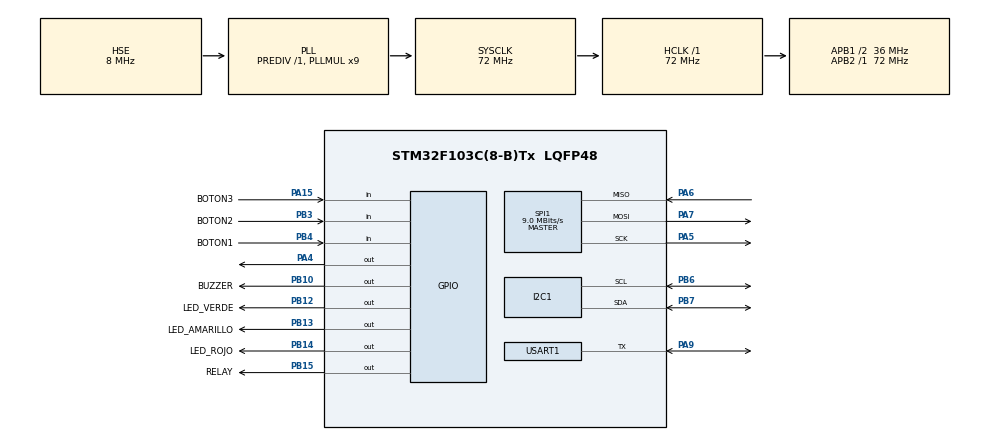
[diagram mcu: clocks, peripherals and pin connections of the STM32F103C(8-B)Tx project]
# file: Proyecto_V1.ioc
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FATFS._MAX_SS=4096
FATFS._USE_LFN=2
FREERTOS.Tasks01=defaultTask,24,128,StartDefaultTask,Default,NULL,Dynamic,NULL,NULL
FREERTOS.configUSE_NEWLIB_REENTRANT=1
Mcu.Family=STM32F1
Mcu.Name=STM32F103C(8-B)Tx
Mcu.Package=LQFP48
NVIC.PriorityGroup=NVIC_PRIORITYGROUP_4
NVIC.TIM4_IRQn=true\:15\:0\:false\:false\:true\:false\:false\:true\:true
NVIC.TimeBase=TIM4_IRQn
NVIC.TimeBaseIP=TIM4
NVIC.USART1_IRQn=true\:5\:0\:false\:false\:true\:true\:true\:true\:true
PA13.Mode=Serial_Wire
PA13.Signal=SYS_JTMS-SWDIO
PA14.Mode=Serial_Wire
PA14.Signal=SYS_JTCK-SWCLK
PA15.GPIO_Label=BOTON3
PA15.GPIO_PuPd=GPIO_PULLUP
PA15.Signal=GPIO_Input
PA4.Signal=GPIO_Output
PA5.Mode=Full_Duplex_Master
PA5.Signal=SPI1_SCK
PA6.Mode=Full_Duplex_Master
PA6.Signal=SPI1_MISO
PA7.Mode=Full_Duplex_Master
PA7.Signal=SPI1_MOSI
PA9.Mode=Half_duplex(single_wire_mode)
PA9.Signal=USART1_TX
PB10.GPIO_Label=BUZZER
PB10.Signal=GPIO_Output
PB12.GPIO_Label=LED_VERDE
PB12.Signal=GPIO_Output
PB13.GPIO_Label=LED_AMARILLO
PB13.Signal=GPIO_Output
PB14.GPIO_Label=LED_ROJO
PB14.Signal=GPIO_Output
PB15.GPIO_Label=RELAY
PB15.Signal=GPIO_Output
PB3.GPIO_Label=BOTON2
PB3.GPIO_PuPd=GPIO_PULLUP
PB3.Signal=GPIO_Input
PB4.GPIO_Label=BOTON1
PB4.GPIO_PuPd=GPIO_PULLUP
PB4.Signal=GPIO_Input
PB6.Mode=I2C
PB6.Signal=I2C1_SCL
PB7.Mode=I2C
PB7.Signal=I2C1_SDA
PD0-OSC_IN.Mode=HSE-External-Oscillator
PD0-OSC_IN.Signal=RCC_OSC_IN
PD1-OSC_OUT.Mode=HSE-External-Oscillator
PD1-OSC_OUT.Signal=RCC_OSC_OUT
ProjectManager.HeapSize=0x200
ProjectManager.StackSize=0x400
ProjectManager.TargetToolchain=STM32CubeIDE
RCC.AHBFreq_Value=72000000
RCC.APB1CLKDivider=RCC_HCLK_DIV2
RCC.APB1Freq_Value=36000000
RCC.APB1TimFreq_Value=72000000
RCC.APB2Freq_Value=72000000
RCC.APB2TimFreq_Value=72000000
RCC.HCLKFreq_Value=72000000
RCC.PLLMUL=RCC_PLL_MUL9
RCC.PLLSourceVirtual=RCC_PLLSOURCE_HSE
RCC.SYSCLKFreq_VALUE=72000000
RCC.SYSCLKSource=RCC_SYSCLKSOURCE_PLLCLK
RCC.USBFreq_Value=72000000
SPI1.BaudRatePrescaler=SPI_BAUDRATEPRESCALER_8
SPI1.CalculateBaudRate=9.0 MBits/s
SPI1.Direction=SPI_DIRECTION_2LINES
SPI1.Mode=SPI_MODE_MASTER
SPI1.VirtualType=VM_MASTER
USART1.VirtualMode=VM_ASYNC
VP_FATFS_VS_Generic.Mode=User_defined
VP_FREERTOS_VS_CMSIS_V2.Mode=CMSIS_V2
VP_SYS_VS_tim4.Mode=TIM4
board=custom

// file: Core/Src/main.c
/* USER CODE BEGIN Header */
/**
  ******************************************************************************
  * @file           : main.c
  * @brief          : Main program body
  ******************************************************************************
  * @attention
  *
  * Copyright (c) 2022 STMicroelectronics.
  * All rights reserved.
  *
  * This software is licensed under terms that can be found in the LICENSE file
  * in the root directory of this software component.
  * If no LICENSE file comes with this software, it is provided AS-IS.
  *
  ******************************************************************************
  */
/* USER CODE END Header */
#include "main.h"
#include "cmsis_os.h"
#include "fatfs.h"

/* USER CODE BEGIN Includes */
#include "liquidcrystal_i2c.h"
#include "OneWire.h"
#include "my_ftoa.h"
#include "funciones.h"
#include "stdio.h"
/* USER CODE END Includes */

 I2C_HandleTypeDef hi2c1;

SPI_HandleTypeDef hspi1;

UART_HandleTypeDef huart1;

/* Definitions for defaultTask */
osThreadId_t defaultTaskHandle;
const osThreadAttr_t defaultTask_attributes = {
  .name = "defaultTask",
  .stack_size = 128 * 4,
  .priority = (osPriority_t) osPriorityNormal,
};

void SystemClock_Config(void);
static void MX_GPIO_Init(void);
static void MX_I2C1_Init(void);
static void MX_USART1_UART_Init(void);
static void MX_SPI1_Init(void);
void StartDefaultTask(void *argument);

/* USER CODE BEGIN 0 */
extern float Temp[MAXDEVICES_ON_THE_BUS];
/* USER CODE END 0 */

int main(void)
{

  /* MCU Configuration--------------------------------------------------------*/

  /* Reset of all peripherals, Initializes the Flash interface and the Systick. */
  HAL_Init();

  /* Configure the system clock */
  SystemClock_Config();

  /* Initialize all configured peripherals */
  MX_GPIO_Init();
  MX_I2C1_Init();
  MX_USART1_UART_Init();
  MX_SPI1_Init();
  MX_FATFS_Init();
  /* USER CODE BEGIN 2 */

  InitAll(); // Inicializa todo

  /* USER CODE END 2 */

  /* Init scheduler */
  osKernelInitialize();

  /* Create the thread(s) */
  /* creation of defaultTask */
  defaultTaskHandle = osThreadNew(StartDefaultTask, NULL, &defaultTask_attributes);

  /* USER CODE BEGIN RTOS_THREADS */
  /* add threads, ... */
  xTaskCreate(MdE_Principal, "MdE Principal", configMINIMAL_STACK_SIZE, NULL, 1, NULL);
  xTaskCreate(MdE_Preparar, "MdE Preparando", configMINIMAL_STACK_SIZE, NULL, 2, NULL);
  xTaskCreate(Tarea_Errores, "Chequeo Errores", configMINIMAL_STACK_SIZE, NULL, 1, NULL);
  xTaskCreate(Tarea_Botones, "Tarea Botones", configMINIMAL_STACK_SIZE, NULL, 1, NULL);
  /* USER CODE END RTOS_THREADS */

  /* Start scheduler */
  osKernelStart();

  /* We should never get here as control is now taken by the scheduler */
  /* Infinite loop */
  while (1)
  {

  }
}

void SystemClock_Config(void)
{
  RCC_OscInitTypeDef RCC_OscInitStruct = {0};
  RCC_ClkInitTypeDef RCC_ClkInitStruct = {0};

  /** Initializes the RCC Oscillators according to the specified parameters
  * in the RCC_OscInitTypeDef structure.
  */
  RCC_OscInitStruct.OscillatorType = RCC_OSCILLATORTYPE_HSE;
  RCC_OscInitStruct.HSEState = RCC_HSE_ON;
  RCC_OscInitStruct.HSEPredivValue = RCC_HSE_PREDIV_DIV1;
  RCC_OscInitStruct.HSIState = RCC_HSI_ON;
  RCC_OscInitStruct.PLL.PLLState = RCC_PLL_ON;
  RCC_OscInitStruct.PLL.PLLSource = RCC_PLLSOURCE_HSE;
  RCC_OscInitStruct.PLL.PLLMUL = RCC_PLL_MUL9;
  if (HAL_RCC_OscConfig(&RCC_OscInitStruct) != HAL_OK)
  {
    Error_Handler();
  }

  /** Initializes the CPU, AHB and APB buses clocks
  */
  RCC_ClkInitStruct.ClockType = RCC_CLOCKTYPE_HCLK|RCC_CLOCKTYPE_SYSCLK
                              |RCC_CLOCKTYPE_PCLK1|RCC_CLOCKTYPE_PCLK2;
  RCC_ClkInitStruct.SYSCLKSource = RCC_SYSCLKSOURCE_PLLCLK;
  RCC_ClkInitStruct.AHBCLKDivider = RCC_SYSCLK_DIV1;
  RCC_ClkInitStruct.APB1CLKDivider = RCC_HCLK_DIV2;
  RCC_ClkInitStruct.APB2CLKDivider = RCC_HCLK_DIV1;

  if (HAL_RCC_ClockConfig(&RCC_ClkInitStruct, FLASH_LATENCY_2) != HAL_OK)
  {
    Error_Handler();
  }
}

static void MX_I2C1_Init(void)
{

  hi2c1.Instance = I2C1;
  hi2c1.Init.ClockSpeed = 100000;
  hi2c1.Init.DutyCycle = I2C_DUTYCYCLE_2;
  hi2c1.Init.OwnAddress1 = 0;
  hi2c1.Init.AddressingMode = I2C_ADDRESSINGMODE_7BIT;
  hi2c1.Init.DualAddressMode = I2C_DUALADDRESS_DISABLE;
  hi2c1.Init.OwnAddress2 = 0;
  hi2c1.Init.GeneralCallMode = I2C_GENERALCALL_DISABLE;
  hi2c1.Init.NoStretchMode = I2C_NOSTRETCH_DISABLE;
  if (HAL_I2C_Init(&hi2c1) != HAL_OK)
  {
    Error_Handler();
  }

}

static void MX_SPI1_Init(void)
{

  /* SPI1 parameter configuration*/
  hspi1.Instance = SPI1;
  hspi1.Init.Mode = SPI_MODE_MASTER;
  hspi1.Init.Direction = SPI_DIRECTION_2LINES;
  hspi1.Init.DataSize = SPI_DATASIZE_8BIT;
  hspi1.Init.CLKPolarity = SPI_POLARITY_LOW;
  hspi1.Init.CLKPhase = SPI_PHASE_1EDGE;
  hspi1.Init.NSS = SPI_NSS_SOFT;
  hspi1.Init.BaudRatePrescaler = SPI_BAUDRATEPRESCALER_8;
  hspi1.Init.FirstBit = SPI_FIRSTBIT_MSB;
  hspi1.Init.TIMode = SPI_TIMODE_DISABLE;
  hspi1.Init.CRCCalculation = SPI_CRCCALCULATION_DISABLE;
  hspi1.Init.CRCPolynomial = 10;
  if (HAL_SPI_Init(&hspi1) != HAL_OK)
  {
    Error_Handler();
  }

}

static void MX_USART1_UART_Init(void)
{

  huart1.Instance = USART1;
  huart1.Init.BaudRate = 115200;
  huart1.Init.WordLength = UART_WORDLENGTH_8B;
  huart1.Init.StopBits = UART_STOPBITS_1;
  huart1.Init.Parity = UART_PARITY_NONE;
  huart1.Init.Mode = UART_MODE_TX_RX;
  huart1.Init.HwFlowCtl = UART_HWCONTROL_NONE;
  huart1.Init.OverSampling = UART_OVERSAMPLING_16;
  if (HAL_HalfDuplex_Init(&huart1) != HAL_OK)
  {
    Error_Handler();
  }

}

static void MX_GPIO_Init(void)
{
  GPIO_InitTypeDef GPIO_InitStruct = {0};

  /* GPIO Ports Clock Enable */
  __HAL_RCC_GPIOD_CLK_ENABLE();
  __HAL_RCC_GPIOA_CLK_ENABLE();
  __HAL_RCC_GPIOB_CLK_ENABLE();

  /*Configure GPIO pin Output Level */
  HAL_GPIO_WritePin(GPIOA, GPIO_PIN_4, GPIO_PIN_RESET);

  /*Configure GPIO pin Output Level */
  HAL_GPIO_WritePin(GPIOB, BUZZER_Pin|LED_VERDE_Pin|LED_AMARILLO_Pin|LED_ROJO_Pin
                          |RELAY_Pin, GPIO_PIN_RESET);

  /*Configure GPIO pin : PA4 */
  GPIO_InitStruct.Pin = GPIO_PIN_4;
  GPIO_InitStruct.Mode = GPIO_MODE_OUTPUT_PP;
  GPIO_InitStruct.Pull = GPIO_NOPULL;
  GPIO_InitStruct.Speed = GPIO_SPEED_FREQ_LOW;
  HAL_GPIO_Init(GPIOA, &GPIO_InitStruct);

  /*Configure GPIO pins : BUZZER_Pin LED_VERDE_Pin LED_AMARILLO_Pin LED_ROJO_Pin
                           RELAY_Pin */
  GPIO_InitStruct.Pin = BUZZER_Pin|LED_VERDE_Pin|LED_AMARILLO_Pin|LED_ROJO_Pin
                          |RELAY_Pin;
  GPIO_InitStruct.Mode = GPIO_MODE_OUTPUT_PP;
  GPIO_InitStruct.Pull = GPIO_NOPULL;
  GPIO_InitStruct.Speed = GPIO_SPEED_FREQ_LOW;
  HAL_GPIO_Init(GPIOB, &GPIO_InitStruct);

  /*Configure GPIO pin : BOTON3_Pin */
  GPIO_InitStruct.Pin = BOTON3_Pin;
  GPIO_InitStruct.Mode = GPIO_MODE_INPUT;
  GPIO_InitStruct.Pull = GPIO_PULLUP;
  HAL_GPIO_Init(BOTON3_GPIO_Port, &GPIO_InitStruct);

  /*Configure GPIO pins : BOTON2_Pin BOTON1_Pin */
  GPIO_InitStruct.Pin = BOTON2_Pin|BOTON1_Pin;
  GPIO_InitStruct.Mode = GPIO_MODE_INPUT;
  GPIO_InitStruct.Pull = GPIO_PULLUP;
  HAL_GPIO_Init(GPIOB, &GPIO_InitStruct);

}

void StartDefaultTask(void *argument)
{
  for(;;)
  {
    osDelay(1);
  }
}

void HAL_TIM_PeriodElapsedCallback(TIM_HandleTypeDef *htim)
{
  if (htim->Instance == TIM4) {
    HAL_IncTick();
  }
}

void Error_Handler(void)
{
  __disable_irq();
  while (1)
  {
  }
}
